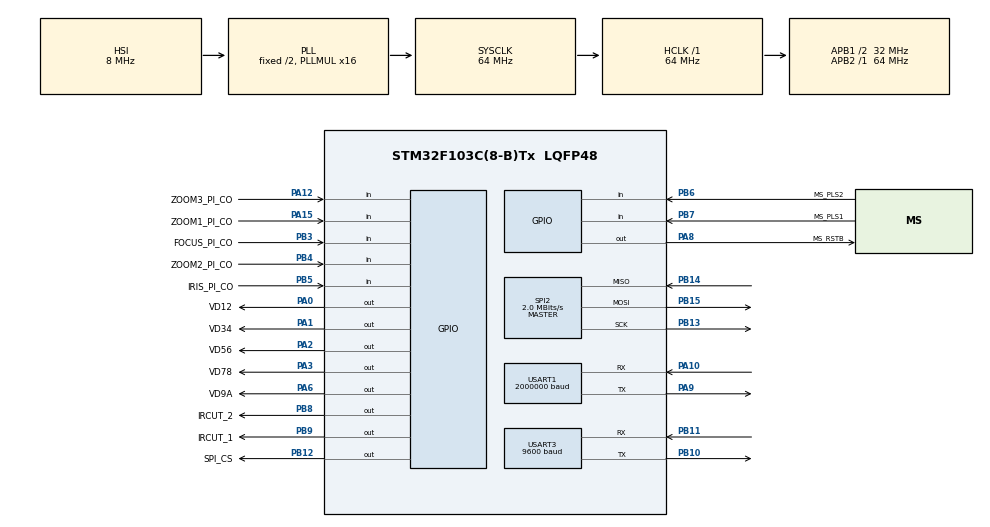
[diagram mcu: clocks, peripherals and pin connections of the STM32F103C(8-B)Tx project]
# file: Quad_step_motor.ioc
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Mcu.Family=STM32F1
Mcu.Name=STM32F103C(8-B)Tx
Mcu.Package=LQFP48
NVIC.PriorityGroup=NVIC_PRIORITYGROUP_4
NVIC.TIM2_IRQn=true\:0\:0\:false\:false\:true\:true\:true\:true
NVIC.TIM3_IRQn=true\:0\:0\:false\:false\:true\:true\:true\:true
NVIC.TIM4_IRQn=true\:0\:0\:false\:false\:true\:true\:true\:true
NVIC.USART1_IRQn=true\:0\:0\:false\:false\:true\:true\:true\:true
NVIC.USART3_IRQn=true\:0\:0\:false\:false\:true\:true\:true\:true
PA0-WKUP.GPIO_Label=VD12
PA0-WKUP.Signal=GPIO_Output
PA1.GPIO_Label=VD34
PA1.Signal=GPIO_Output
PA10.Mode=Asynchronous
PA10.Signal=USART1_RX
PA12.GPIO_Label=ZOOM3_PI_CO
PA12.Signal=GPIO_Input
PA13.Mode=Serial_Wire
PA13.Signal=SYS_JTMS-SWDIO
PA14.Mode=Serial_Wire
PA14.Signal=SYS_JTCK-SWCLK
PA15.GPIO_Label=ZOOM1_PI_CO
PA15.Signal=GPIO_Input
PA2.GPIO_Label=VD56
PA2.Signal=GPIO_Output
PA3.GPIO_Label=VD78
PA3.Signal=GPIO_Output
PA6.GPIO_Label=VD9A
PA6.Signal=GPIO_Output
PA8.GPIO_Label=MS_RSTB
PA8.Signal=GPIO_Output
PA9.Mode=Asynchronous
PA9.Signal=USART1_TX
PB10.Mode=Asynchronous
PB10.Signal=USART3_TX
PB11.Mode=Asynchronous
PB11.Signal=USART3_RX
PB12.GPIO_Label=SPI_CS
PB12.Signal=GPIO_Output
PB13.Mode=Full_Duplex_Master
PB13.Signal=SPI2_SCK
PB14.Mode=Full_Duplex_Master
PB14.Signal=SPI2_MISO
PB15.Mode=Full_Duplex_Master
PB15.Signal=SPI2_MOSI
PB3.GPIO_Label=FOCUS_PI_CO
PB3.Signal=GPIO_Input
PB4.GPIO_Label=ZOOM2_PI_CO
PB4.Signal=GPIO_Input
PB5.GPIO_Label=IRIS_PI_CO
PB5.Signal=GPIO_Input
PB6.GPIO_Label=MS_PLS2
PB6.Signal=GPIO_Input
PB7.GPIO_Label=MS_PLS1
PB7.Signal=GPIO_Input
PB8.GPIO_Label=IRCUT_2
PB8.Signal=GPIO_Output
PB9.GPIO_Label=IRCUT_1
PB9.Signal=GPIO_Output
ProjectManager.HeapSize=0x200
ProjectManager.StackSize=0x400
ProjectManager.TargetToolchain=STM32CubeIDE
RCC.AHBFreq_Value=64000000
RCC.APB1CLKDivider=RCC_HCLK_DIV2
RCC.APB1Freq_Value=32000000
RCC.APB1TimFreq_Value=64000000
RCC.APB2Freq_Value=64000000
RCC.APB2TimFreq_Value=64000000
RCC.HCLKFreq_Value=64000000
RCC.PLLMUL=RCC_PLL_MUL16
RCC.SYSCLKFreq_VALUE=64000000
RCC.SYSCLKSource=RCC_SYSCLKSOURCE_PLLCLK
RCC.USBFreq_Value=64000000
SPI2.BaudRatePrescaler=SPI_BAUDRATEPRESCALER_16
SPI2.CLKPhase=SPI_PHASE_2EDGE
SPI2.CLKPolarity=SPI_POLARITY_HIGH
SPI2.CalculateBaudRate=2.0 MBits/s
SPI2.Direction=SPI_DIRECTION_2LINES
SPI2.FirstBit=SPI_FIRSTBIT_LSB
SPI2.Mode=SPI_MODE_MASTER
SPI2.VirtualType=VM_MASTER
TIM2.Period=999
TIM2.Prescaler=64-1
TIM4.Period=999
TIM4.Prescaler=64-1
USART1.BaudRate=2000000
USART1.VirtualMode=VM_ASYNC
USART3.BaudRate=9600
USART3.VirtualMode=VM_ASYNC
VP_TIM2_VS_ClockSourceINT.Mode=Internal
VP_TIM3_VS_ClockSourceINT.Mode=Internal
VP_TIM4_VS_ClockSourceINT.Mode=Internal
board=custom

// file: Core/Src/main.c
/* USER CODE BEGIN Header */
/**
  ******************************************************************************
  * @file           : main.c
  * @brief          : Main program body
  ******************************************************************************
  * @attention
  *
  * Copyright (c) 2025 STMicroelectronics.
  * All rights reserved.
  *
  * This software is licensed under terms that can be found in the LICENSE file
  * in the root directory of this software component.
  * If no LICENSE file comes with this software, it is provided AS-IS.
  *
  ******************************************************************************
  */
/* USER CODE END Header */
#include "main.h"

SPI_HandleTypeDef hspi2;

TIM_HandleTypeDef htim2;
TIM_HandleTypeDef htim3;
TIM_HandleTypeDef htim4;

UART_HandleTypeDef huart1;
UART_HandleTypeDef huart3;

void SystemClock_Config(void);
static void MX_GPIO_Init(void);
static void MX_SPI2_Init(void);
static void MX_TIM2_Init(void);
static void MX_USART1_UART_Init(void);
static void MX_USART3_UART_Init(void);
static void MX_TIM4_Init(void);
static void MX_TIM3_Init(void);

int main(void)
{

  /* MCU Configuration--------------------------------------------------------*/

  /* Reset of all peripherals, Initializes the Flash interface and the Systick. */
  HAL_Init();

  /* Configure the system clock */
  SystemClock_Config();

  /* Initialize all configured peripherals */
  MX_GPIO_Init();
  MX_SPI2_Init();
  MX_TIM2_Init();
  MX_USART1_UART_Init();
  MX_USART3_UART_Init();
  MX_TIM4_Init();
  MX_TIM3_Init();

  /* Infinite loop */
  /* USER CODE BEGIN WHILE */
  while (1)
  {
	  User_main();
    /* USER CODE END WHILE */

  }
}

void SystemClock_Config(void)
{
  RCC_OscInitTypeDef RCC_OscInitStruct = {0};
  RCC_ClkInitTypeDef RCC_ClkInitStruct = {0};

  /** Initializes the RCC Oscillators according to the specified parameters
  * in the RCC_OscInitTypeDef structure.
  */
  RCC_OscInitStruct.OscillatorType = RCC_OSCILLATORTYPE_HSI;
  RCC_OscInitStruct.HSIState = RCC_HSI_ON;
  RCC_OscInitStruct.HSICalibrationValue = RCC_HSICALIBRATION_DEFAULT;
  RCC_OscInitStruct.PLL.PLLState = RCC_PLL_ON;
  RCC_OscInitStruct.PLL.PLLSource = RCC_PLLSOURCE_HSI_DIV2;
  RCC_OscInitStruct.PLL.PLLMUL = RCC_PLL_MUL16;
  if (HAL_RCC_OscConfig(&RCC_OscInitStruct) != HAL_OK)
  {
    Error_Handler();
  }

  /** Initializes the CPU, AHB and APB buses clocks
  */
  RCC_ClkInitStruct.ClockType = RCC_CLOCKTYPE_HCLK|RCC_CLOCKTYPE_SYSCLK
                              |RCC_CLOCKTYPE_PCLK1|RCC_CLOCKTYPE_PCLK2;
  RCC_ClkInitStruct.SYSCLKSource = RCC_SYSCLKSOURCE_PLLCLK;
  RCC_ClkInitStruct.AHBCLKDivider = RCC_SYSCLK_DIV1;
  RCC_ClkInitStruct.APB1CLKDivider = RCC_HCLK_DIV2;
  RCC_ClkInitStruct.APB2CLKDivider = RCC_HCLK_DIV1;

  if (HAL_RCC_ClockConfig(&RCC_ClkInitStruct, FLASH_LATENCY_2) != HAL_OK)
  {
    Error_Handler();
  }
}

static void MX_SPI2_Init(void)
{

  /* SPI2 parameter configuration*/
  hspi2.Instance = SPI2;
  hspi2.Init.Mode = SPI_MODE_MASTER;
  hspi2.Init.Direction = SPI_DIRECTION_2LINES;
  hspi2.Init.DataSize = SPI_DATASIZE_8BIT;
  hspi2.Init.CLKPolarity = SPI_POLARITY_HIGH;
  hspi2.Init.CLKPhase = SPI_PHASE_2EDGE;
  hspi2.Init.NSS = SPI_NSS_SOFT;
  hspi2.Init.BaudRatePrescaler = SPI_BAUDRATEPRESCALER_16;
  hspi2.Init.FirstBit = SPI_FIRSTBIT_LSB;
  hspi2.Init.TIMode = SPI_TIMODE_DISABLE;
  hspi2.Init.CRCCalculation = SPI_CRCCALCULATION_DISABLE;
  hspi2.Init.CRCPolynomial = 10;
  if (HAL_SPI_Init(&hspi2) != HAL_OK)
  {
    Error_Handler();
  }

}

static void MX_TIM2_Init(void)
{

  TIM_ClockConfigTypeDef sClockSourceConfig = {0};
  TIM_MasterConfigTypeDef sMasterConfig = {0};

  htim2.Instance = TIM2;
  htim2.Init.Prescaler = 64-1;
  htim2.Init.CounterMode = TIM_COUNTERMODE_UP;
  htim2.Init.Period = 999;
  htim2.Init.ClockDivision = TIM_CLOCKDIVISION_DIV1;
  htim2.Init.AutoReloadPreload = TIM_AUTORELOAD_PRELOAD_DISABLE;
  if (HAL_TIM_Base_Init(&htim2) != HAL_OK)
  {
    Error_Handler();
  }
  sClockSourceConfig.ClockSource = TIM_CLOCKSOURCE_INTERNAL;
  if (HAL_TIM_ConfigClockSource(&htim2, &sClockSourceConfig) != HAL_OK)
  {
    Error_Handler();
  }
  sMasterConfig.MasterOutputTrigger = TIM_TRGO_RESET;
  sMasterConfig.MasterSlaveMode = TIM_MASTERSLAVEMODE_DISABLE;
  if (HAL_TIMEx_MasterConfigSynchronization(&htim2, &sMasterConfig) != HAL_OK)
  {
    Error_Handler();
  }

}

static void MX_TIM3_Init(void)
{

  TIM_ClockConfigTypeDef sClockSourceConfig = {0};
  TIM_MasterConfigTypeDef sMasterConfig = {0};

  htim3.Instance = TIM3;
  htim3.Init.Prescaler = 0;
  htim3.Init.CounterMode = TIM_COUNTERMODE_UP;
  htim3.Init.Period = 65535;
  htim3.Init.ClockDivision = TIM_CLOCKDIVISION_DIV1;
  htim3.Init.AutoReloadPreload = TIM_AUTORELOAD_PRELOAD_DISABLE;
  if (HAL_TIM_Base_Init(&htim3) != HAL_OK)
  {
    Error_Handler();
  }
  sClockSourceConfig.ClockSource = TIM_CLOCKSOURCE_INTERNAL;
  if (HAL_TIM_ConfigClockSource(&htim3, &sClockSourceConfig) != HAL_OK)
  {
    Error_Handler();
  }
  sMasterConfig.MasterOutputTrigger = TIM_TRGO_RESET;
  sMasterConfig.MasterSlaveMode = TIM_MASTERSLAVEMODE_DISABLE;
  if (HAL_TIMEx_MasterConfigSynchronization(&htim3, &sMasterConfig) != HAL_OK)
  {
    Error_Handler();
  }

}

static void MX_TIM4_Init(void)
{

  TIM_ClockConfigTypeDef sClockSourceConfig = {0};
  TIM_MasterConfigTypeDef sMasterConfig = {0};

  htim4.Instance = TIM4;
  htim4.Init.Prescaler = 64-1;
  htim4.Init.CounterMode = TIM_COUNTERMODE_UP;
  htim4.Init.Period = 999;
  htim4.Init.ClockDivision = TIM_CLOCKDIVISION_DIV1;
  htim4.Init.AutoReloadPreload = TIM_AUTORELOAD_PRELOAD_DISABLE;
  if (HAL_TIM_Base_Init(&htim4) != HAL_OK)
  {
    Error_Handler();
  }
  sClockSourceConfig.ClockSource = TIM_CLOCKSOURCE_INTERNAL;
  if (HAL_TIM_ConfigClockSource(&htim4, &sClockSourceConfig) != HAL_OK)
  {
    Error_Handler();
  }
  sMasterConfig.MasterOutputTrigger = TIM_TRGO_RESET;
  sMasterConfig.MasterSlaveMode = TIM_MASTERSLAVEMODE_DISABLE;
  if (HAL_TIMEx_MasterConfigSynchronization(&htim4, &sMasterConfig) != HAL_OK)
  {
    Error_Handler();
  }

}

static void MX_USART1_UART_Init(void)
{

  huart1.Instance = USART1;
  huart1.Init.BaudRate = 2000000;
  huart1.Init.WordLength = UART_WORDLENGTH_8B;
  huart1.Init.StopBits = UART_STOPBITS_1;
  huart1.Init.Parity = UART_PARITY_NONE;
  huart1.Init.Mode = UART_MODE_TX_RX;
  huart1.Init.HwFlowCtl = UART_HWCONTROL_NONE;
  huart1.Init.OverSampling = UART_OVERSAMPLING_16;
  if (HAL_UART_Init(&huart1) != HAL_OK)
  {
    Error_Handler();
  }

}

static void MX_USART3_UART_Init(void)
{

  huart3.Instance = USART3;
  huart3.Init.BaudRate = 9600;
  huart3.Init.WordLength = UART_WORDLENGTH_8B;
  huart3.Init.StopBits = UART_STOPBITS_1;
  huart3.Init.Parity = UART_PARITY_NONE;
  huart3.Init.Mode = UART_MODE_TX_RX;
  huart3.Init.HwFlowCtl = UART_HWCONTROL_NONE;
  huart3.Init.OverSampling = UART_OVERSAMPLING_16;
  if (HAL_UART_Init(&huart3) != HAL_OK)
  {
    Error_Handler();
  }

}

static void MX_GPIO_Init(void)
{
  GPIO_InitTypeDef GPIO_InitStruct = {0};

  /* GPIO Ports Clock Enable */
  __HAL_RCC_GPIOA_CLK_ENABLE();
  __HAL_RCC_GPIOB_CLK_ENABLE();

  /*Configure GPIO pin Output Level */
  HAL_GPIO_WritePin(GPIOA, VD12_Pin|VD34_Pin|VD56_Pin|VD78_Pin
                          |VD9A_Pin|MS_RSTB_Pin, GPIO_PIN_RESET);

  /*Configure GPIO pin Output Level */
  HAL_GPIO_WritePin(GPIOB, SPI_CS_Pin|IRCUT_2_Pin|IRCUT_1_Pin, GPIO_PIN_RESET);

  /*Configure GPIO pins : VD12_Pin VD34_Pin VD56_Pin VD78_Pin
                           VD9A_Pin MS_RSTB_Pin */
  GPIO_InitStruct.Pin = VD12_Pin|VD34_Pin|VD56_Pin|VD78_Pin
                          |VD9A_Pin|MS_RSTB_Pin;
  GPIO_InitStruct.Mode = GPIO_MODE_OUTPUT_PP;
  GPIO_InitStruct.Pull = GPIO_NOPULL;
  GPIO_InitStruct.Speed = GPIO_SPEED_FREQ_LOW;
  HAL_GPIO_Init(GPIOA, &GPIO_InitStruct);

  /*Configure GPIO pins : SPI_CS_Pin IRCUT_2_Pin IRCUT_1_Pin */
  GPIO_InitStruct.Pin = SPI_CS_Pin|IRCUT_2_Pin|IRCUT_1_Pin;
  GPIO_InitStruct.Mode = GPIO_MODE_OUTPUT_PP;
  GPIO_InitStruct.Pull = GPIO_NOPULL;
  GPIO_InitStruct.Speed = GPIO_SPEED_FREQ_LOW;
  HAL_GPIO_Init(GPIOB, &GPIO_InitStruct);

  /*Configure GPIO pins : ZOOM3_PI_CO_Pin ZOOM1_PI_CO_Pin */
  GPIO_InitStruct.Pin = ZOOM3_PI_CO_Pin|ZOOM1_PI_CO_Pin;
  GPIO_InitStruct.Mode = GPIO_MODE_INPUT;
  GPIO_InitStruct.Pull = GPIO_NOPULL;
  HAL_GPIO_Init(GPIOA, &GPIO_InitStruct);

  /*Configure GPIO pins : FOCUS_PI_CO_Pin ZOOM2_PI_CO_Pin IRIS_PI_CO_Pin MS_PLS2_Pin
                           MS_PLS1_Pin */
  GPIO_InitStruct.Pin = FOCUS_PI_CO_Pin|ZOOM2_PI_CO_Pin|IRIS_PI_CO_Pin|MS_PLS2_Pin
                          |MS_PLS1_Pin;
  GPIO_InitStruct.Mode = GPIO_MODE_INPUT;
  GPIO_InitStruct.Pull = GPIO_NOPULL;
  HAL_GPIO_Init(GPIOB, &GPIO_InitStruct);

}

void Error_Handler(void)
{
  __disable_irq();
  while (1)
  {
  }
}
